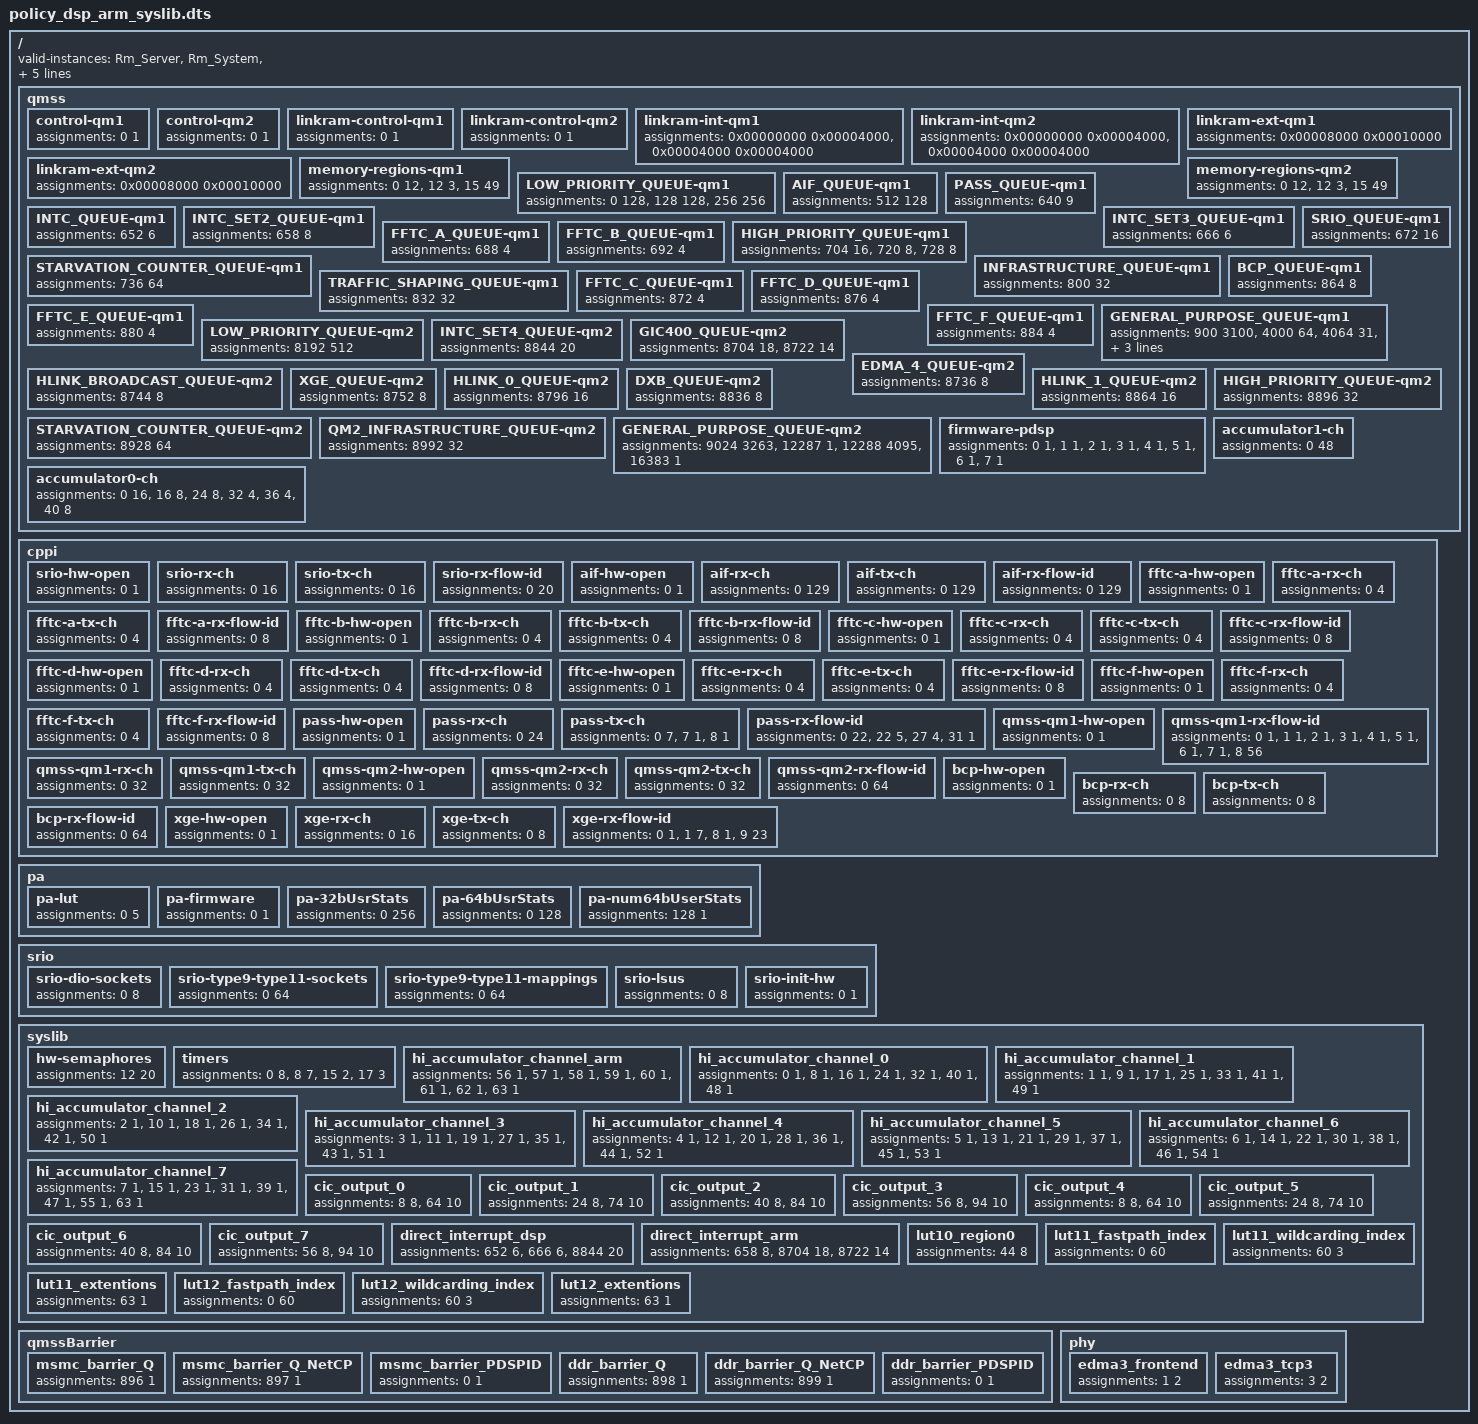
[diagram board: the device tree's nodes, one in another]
/dts-v1/;

/* Keystone II policy containing reserving resources used by Linux Kernel */

/ {
    /* List of Instance names: */
    valid-instances = "Rm_Server",
                      "Rm_System",
                      "Rm_LTE10",
                      "Rm_LTE10_L3",
                      "Rm_LTE10_L2",
                      "Rm_LTE10_L2A",
                      "Rm_LTE10_L2B",
                      "Rm_LTE10_L1A",
                      "Rm_LTE10_L1B",
                      "Rm_LTE9A",
                      "Rm_LTE9A_L1",
                      "Rm_LTE9A_L2",
                      "Rm_LTE9B",
                      "Rm_LTE9B_L1",
                      "Rm_LTE9B_L2";
    qmss {
        /* QMSS in joint mode affects only -qm1 resource */
        control-qm1 {
            assignments = <0 1>, "iu = (*)";
        };
        control-qm2 {
            assignments = <0 1>, "iu = (*)";
        };

        linkram-control-qm1 {
            assignments = <0 1>, "(*)";             /* Used by Kernel */
        };
        linkram-control-qm2 {
            assignments = <0 1>, "(*)";             /* Used by Kernel */
        };

        linkram-int-qm1 {
            /* linux provided 0x18000 descriptors of linking RAM but uses 0x4000 to 0x8000 */
            assignments = <0x00000000 0x00004000>, "iu = (*)",
                          <0x00004000 0x00004000>, "(*)"; /* Used by Kernel */
        };
        linkram-int-qm2 {
            /* linux provided 0x18000 descriptors of linking RAM but uses 0x4000 to 0x8000 */
            assignments = <0x00000000 0x00004000>, "iu = (*)",
                          <0x00004000 0x00004000>, "(*)"; /* Used by Kernel */
        };
        linkram-ext-qm1 {
            assignments = <0x00008000 0x00010000>, "iu = (*)";
        };
        linkram-ext-qm2 {
            assignments = <0x00008000 0x00010000>, "iu = (*)";
        };

        memory-regions-qm1 {
            assignments = <0  12>, "iu = (*)",
                          <12 3>,  "(*)",             /* Used by Kernel */
                          <15 49>, "iu = (*)";
        };
        memory-regions-qm2 {
            assignments = <0  12>, "iu = (*)",
                          <12 3>,  "(*)",             /* Used by Kernel */
                          <15 49>, "iu = (*)";
        };

        LOW_PRIORITY_QUEUE-qm1 {
            /* this is loosely coupled with accumulator-ch channels 32-47.  These queues are
             * just suggested to be paired with these channels, the accumulator can be sw
             * configured to use any queue */
            assignments = <0 128>,   "iu = (*)", /* suggested for channels 32-35 */
                          <128 128>, "     (*)", /* used by linux (accumulator-low-#); linux pairs these to channels 36-39 */
                          <256 256>, "iu = (*)"; /* suggested for channels 40-47 */
        };
        AIF_QUEUE-qm1 {
            assignments = <512 128>, "iu = (*)";
        };
        PASS_QUEUE-qm1 {
            assignments = <640  9>,  "iu = (*)";     /* used by both kernel and DSP */
        };
        INTC_QUEUE-qm1 {
            assignments = <652 6>, "iu = (*)";
        };
        INTC_SET2_QUEUE-qm1 {
            assignments = <658 8>, "iu = (*)";
        };
        INTC_SET3_QUEUE-qm1 {
            assignments = <666 6>, "iu = (*)";
        };
        SRIO_QUEUE-qm1 {
            assignments = <672 16>, "iu = (*)";
        };
        FFTC_A_QUEUE-qm1 {
            assignments = <688 4>, "iu = (*)";
        };
        FFTC_B_QUEUE-qm1 {
            assignments = <692 4>, "iu = (*)";
        };
        HIGH_PRIORITY_QUEUE-qm1 {
            /* this is loosely coupled with accumulator-ch channels 0-15.  These queues are
             * just suggested to be paired with these channels, the accumulator can be sw
             * configured to use any queue */
            assignments = <704 16>, "iu = (*)", /* suggested for channels 0-15 */
                          <720 8>,  "iu = (*)", /* Declared, but not used, by linux (accumulator-high.values). */
                          <728 8>,  "iu = (*)"; /* suggested for channels 24-31 */
        };
        STARVATION_COUNTER_QUEUE-qm1 {
            assignments = <736 64>, "iu = (*)";
        };
        INFRASTRUCTURE_QUEUE-qm1 {
            assignments = <800  32>,   "iu = (*)";
        };
        TRAFFIC_SHAPING_QUEUE-qm1 {
            assignments = <832 32>, "iu = (*)";
        };
        BCP_QUEUE-qm1 {
            assignments = <864 8>, "iu = (*)";
        };
        FFTC_C_QUEUE-qm1 {
            assignments = <872 4>, "iu = (*)";
        };
        FFTC_D_QUEUE-qm1 {
            assignments = <876 4>, "iu = (*)";
        };
        FFTC_E_QUEUE-qm1 {
            assignments = <880 4>, "iu = (*)";
        };
        FFTC_F_QUEUE-qm1 {
            assignments = <884 4>, "iu = (*)";
        };
        GENERAL_PURPOSE_QUEUE-qm1 {
            assignments = /* First 4 queues are reserved for QMSS barrier */
                          /*<896  4>,     "iu = (Rm_System)",*/
                          <900  3100>,  "iu = (*)",
                          <4000 64>,    "(*)",       /* Used by Kernel */
                          <4064 31>,    "iu = (*)",
                          <4095 1>,     "iue = (*)",   /* Queues ending in 0xfff can't be used as return queue (hw reserved) */
                          <4096 2304>,  "iu = (*)",

                          /* 6400-6477 is taken by linux for qostree2, but DSP can transmit via "fastpath" queues */
                          <6400 72>,    "u = (*)",   /* qos queues for DSP (fastpath-best-effort, fastpath-hp, 4g-cos#, 3g-cos#, wifi-cos#) use (open by number) not init */
                          <6472 6>,     "(*)",       /* qos queues for linux (linux-best-effort, linux-cos#, linux-hp) - DSP can't use */
                          <6478 114>,   "(*)",       /* unconfigured QoS/Linux queues (qos-inputs-2) */

                          <6592 1408>,  "iu = (*)",

                          /* 8000-8191 is taken by linux for qostree but DSP can transmit via "fastpath" queues */
                          <8000 72>,    "u = (*)",   /* qos queues for DSP (fastpath-best-effort, fastpath-hp, 4g-cos#, 3g-cos#, wifi-cos#) use (open by number) not init */
                          <8072 6>,     "(*)",       /* qos queues for linux (linux-best-effort, linux-cos#, linux-hp) - DSP can't use */
                          <8078 114>,   "(*)";       /* unconfigured QoS/Linux queues (qos-inputs-1) */
                                                     /* note for q 8191: Queues ending in 0xfff can't be used as return queue (hw reserved) */
        };
        LOW_PRIORITY_QUEUE-qm2 {
            assignments = <8192 512>, "iu = (*)";
        };
        INTC_SET4_QUEUE-qm2 {
            assignments = <8844 20>, "iu = (*)";
        };
        GIC400_QUEUE-qm2 {
            assignments = <8704 18>,    "(*)",             /* Used by Kernel */
                          <8722 14>,   "iu = (*)";
        };
        EDMA_4_QUEUE-qm2 {
            assignments = <8736 8>, "iu = (*)";
        };
        HLINK_BROADCAST_QUEUE-qm2 {
            assignments = <8744 8>, "iu = (*)";
        };
        XGE_QUEUE-qm2 {
            assignments = <8752 8>, "iu = (*)";   /* can be used by both dsp and kernel */
        };
        HLINK_0_QUEUE-qm2 {
            assignments = <8796 16>, "iu = (*)";
        };
        DXB_QUEUE-qm2 {
            assignments = <8836 8>, "iu = (*)";
        };
        HLINK_1_QUEUE-qm2 {
            assignments = <8864 16>, "iu = (*)";
        };
        HIGH_PRIORITY_QUEUE-qm2 {
            assignments = <8896 32>, "iu = (*)";
        };
        STARVATION_COUNTER_QUEUE-qm2 {
            assignments = <8928 64>, "iu = (*)";
        };
        QM2_INFRASTRUCTURE_QUEUE-qm2 {
            assignments = <8992 32>, "iu = (*)";
        };
        GENERAL_PURPOSE_QUEUE-qm2 {
            assignments = <9024 3263>, "iu = (*)",
                          <12287 1>, "iue = (*)", /* Queues ending in 0xfff can't be used as return queue (hw reserved) */
                          <12288 4095>, "iu = (*)",
                          <16383 1>, "iue = (*)"; /* Queues ending in 0xfff can't be used as return queue (hw reserved) */
        }; 
        
        firmware-pdsp {
            assignments = <0 1>, "     (*)", /* pdsp0: accumulator 0 downloaded by linux */
                          <1 1>, "iu = (*)", /* pdsp1: for em scheduler if event machine is used (not downloaded by linux) */
                          <2 1>, "iu = (Rm_System)", /* pdsp2: for accumulator 1 on second intd (not downloaded by linux) */
                          <3 1>, "     (*)", /* pdsp3: qostree downloaded by linux */
                          <4 1>, "iu = (*)", /* pdsp4: for em scheduler if event machine is used (not downloaded by linux) */
                          <5 1>, "iu = (*)", /* pdsp5: for em scheduler if event machine is used (not downloaded by linux) */
                          <6 1>, "iu = (*)", /* pdsp6: for em router if event machine is used (not downloaded by linux) */
                          <7 1>, "     (*)"; /* pdsp7: qostree2 downloaded by linux */
        };
        accumulator0-ch { /* accumulator using first INTD */
            assignments = <0 16>, "iu = (*)",    /* high priority 0-15 available for everyone */
                          <16 8>, "iu = (*)",    /* declared but not used by linux, subject to change */
                          <24 8>, "iu = (*)",    /* last 8 high priority are used by event machine, available in non EM use case */
                          <32 4>, "iu = (*)",    /* first 4 low priority are used by event machine, available in non EM use case */
                          <36 4>, "     (*)",    /* next 4 low priority are used by linux (accumulator-low-#) */
                          <40 8>, "iu = (*)";    /* available for all */
        };
        accumulator1-ch { /* accumulator using second INTD */
            assignments = <0 48>, "iu = (*)";    /* linux doesn't use it */
        };
    }; /* qmss */

    cppi {
        srio-hw-open {
            assignments = <0 1>, "iu = (*)";
        };
        srio-rx-ch {
            assignments = <0 16>, "iu = (*)";
        };
        srio-tx-ch {
            assignments = <0 16>, "iu = (*)";
        };
        srio-rx-flow-id {
            assignments = <0 20>, "iu = (*)";
        };   

        aif-hw-open {
            assignments = <0 1>, "iu = (*)";
        };
        aif-rx-ch {
            assignments = <0 129>, "iu = (*)";
        };
        aif-tx-ch {
            assignments = <0 129>, "iu = (*)";
        };
        aif-rx-flow-id {
            assignments = <0 129>, "iu = (*)";
        };      

        fftc-a-hw-open {
            assignments = <0 1>, "iu = (*)";
        };
        fftc-a-rx-ch {
            assignments = <0 4>, "iu = (*)";
        };
        fftc-a-tx-ch {
            assignments = <0 4>, "iu = (*)";
        };
        fftc-a-rx-flow-id {
            assignments = <0 8>, "iu = (*)";
        };   

        fftc-b-hw-open {
            assignments = <0 1>, "iu = (*)";
        };
        fftc-b-rx-ch {
            assignments = <0 4>, "iu = (*)";
        };
        fftc-b-tx-ch {
            assignments = <0 4>, "iu = (*)";
        };
        fftc-b-rx-flow-id {
            assignments = <0 8>, "iu = (*)";
        };   

        fftc-c-hw-open {
            assignments = <0 1>, "iu = (*)";
        };
        fftc-c-rx-ch {
            assignments = <0 4>, "iu = (*)";
        };
        fftc-c-tx-ch {
            assignments = <0 4>, "iu = (*)";
        };
        fftc-c-rx-flow-id {
            assignments = <0 8>, "iu = (*)";
        };

        fftc-d-hw-open {
            assignments = <0 1>, "iu = (*)";
        };
        fftc-d-rx-ch {
            assignments = <0 4>, "iu = (*)";
        };
        fftc-d-tx-ch {
            assignments = <0 4>, "iu = (*)";
        };
        fftc-d-rx-flow-id {
            assignments = <0 8>, "iu = (*)";
        };   

        fftc-e-hw-open {
            assignments = <0 1>, "iu = (*)";
        };
        fftc-e-rx-ch {
            assignments = <0 4>, "iu = (*)";
        };
        fftc-e-tx-ch {
            assignments = <0 4>, "iu = (*)";
        };
        fftc-e-rx-flow-id {
            assignments = <0 8>, "iu = (*)";
        };

        fftc-f-hw-open {
            assignments = <0 1>, "iu = (*)";
        };
        fftc-f-rx-ch {
            assignments = <0 4>, "iu = (*)";
        };
        fftc-f-tx-ch {
            assignments = <0 4>, "iu = (*)";
        };
        fftc-f-rx-flow-id {
            assignments = <0 8>, "iu = (*)";
        };         
        
        pass-hw-open {
            assignments = <0 1>, "iu = (*)";
        };
        pass-rx-ch {
            assignments = <0 24>, "     (*)"; /* initialized by kernel */
        };
        pass-tx-ch {
            assignments = <0 7>, "     (*)", /* initialized by kernel, can directly open queuse */
                          <7 1>, "iu = (*)", /* SA channel.  Linux initializes, but some applications need to enable/disable on fly */
                          <8 1>, "     (*)"; /* initialized by kernel, can directly open queuse */
        };
        pass-rx-flow-id {
            assignments = <0 22>, "iu = (*)", /* available */
                          <22 5>, "     (*)", /* used by kernel (netrx0, netrx1, netrx2, netrx3, crypto-rx0) */
                          <27 4>, "iu = (*)", /* available */
                          <31 1>, "     (*)"; /* used by kernel (parx) */
        };

        qmss-qm1-hw-open {
            assignments = <0 1>, "iu = (*)";
        };
/*
        qmss-qm1-rx-ch {
            assignments = <0 32>, "iu = (*)";
        };
        qmss-qm1-tx-ch {
            assignments = <0 32>, "iu = (*)";
        };
        qmss-qm1-rx-flow-id {
            assignments = <0 64>, "iu = (*)";
        };
*/
        /*****************************************************************************************
         * NOTE: The name proxy(s) for DSP-ARM communication reserves 2 sets of infrastructure
         * resources which are required used by the agent server in each realm.
         *
         * LTE9A RAT ARM Agent Server resource usage
         *    Local Flow Id  0 :
         *    Rx Channel     0 :
         *    Tx Channel     1 :
         *
         * LTE9A RAT DSP Agent Server resource usage
         *    Local Flow Id  1 :
         *    Rx Channel     1 :
         *    Tx Channel     0 :
         *
         * LTE9A RAT ARM Agent Server resource usage
         *    Local Flow Id  2 :
         *    Rx Channel     2 :
         *    Tx Channel     3 :
         *
         * LTE9A RAT DSP Agent Server resource usage
         *    Local Flow Id  3 :
         *    Rx Channel     3 :
         *    Tx Channel     2 :
         *
         * It is assumed that the name proxy in the DSP is executing in the L2 domain. If this is
         * not the case please change the RM client name accordingly.
         *
         * For the Release 10; the name proxy will execute on the DSP in the L1 domain. The L2 domain
         * whether it executes on DSP/ARM will also execute the name proxy. There could be 2 L2
         * domains L2A handling L1A and L2B handling L2B.
         *
         * The convention is that Flow Id 0, 2, 4, 6 are always used by the SYSLIB servers.
         * Flow Id 1, 3, 5, 7 are available to the applications.
         ********************************************************************************************/
        qmss-qm1-rx-flow-id {
            assignments = <0 1>,  "iu = (Rm_LTE9A Rm_LTE10)",
                          <1 1>,  "iu = (Rm_LTE9A_L2 Rm_LTE10_L1A)",
                          <2 1>,  "iu = (Rm_LTE9B Rm_LTE10)",
                          <3 1>,  "iu = (Rm_LTE9B_L2 Rm_LTE10_L1B)",
                          <4 1>,  "iu = (Rm_LTE10)",
                          <5 1>,  "iu = (Rm_LTE10_L2A)",
                          <6 1>,  "iu = (Rm_LTE10)",
                          <7 1>,  "iu = (Rm_LTE10_L2B)",
                          <8 56>, "iu = (*)";
        };
        qmss-qm1-rx-ch {
            assignments = <0 32>, "iu = (*)";
        };
        qmss-qm1-tx-ch {
            assignments = <0 32>, "iu = (*)";
        };

        qmss-qm2-hw-open {
            assignments = <0 1>, "iu = (*)";
        };
        qmss-qm2-rx-ch {
            assignments = <0 32>, "iu = (*)";
        };
        qmss-qm2-tx-ch {
            assignments = <0 32>, "iu = (*)";
        };
        qmss-qm2-rx-flow-id {
            assignments = <0 64>, "iu = (*)";
        };

        bcp-hw-open {
            assignments = <0 1>, "iu = (*)";
        };
        bcp-rx-ch {
            assignments = <0 8>, "iu = (*)";
        };
        bcp-tx-ch {
            assignments = <0 8>, "iu = (*)";
        };
        bcp-rx-flow-id {
            assignments = <0 64>, "iu = (*)";
        };

        xge-hw-open {
            assignments = <0 1>, "iu = (*)";
        };
        xge-rx-ch {
            assignments = <0 16>, "    (*)"; /* initialized by kernel */
        };
        xge-tx-ch {
            assignments = <0 8>, "     (*)"; /* initialized by kernel, directly open the queues */
        };
        xge-rx-flow-id {
            assignments = <0 1>,  "     (*)", /* used by kernel (xgerx0) */
                          <1 7>,  "iu = (*)", /* available */
                          <8 1>,  "     (*)", /* used by kernel (xgerx1) */
                          <9 23>, "iu = (*)"; /* available */
        };
    }; /* cppi */

    pa {
        pa-lut {
            assignments = <0 5>, "iu = (*)";
        };
        pa-firmware {
            assignments = <0 1>, "(*)"; /* linux downloads PA firmware */
        };
        pa-32bUsrStats {
            assignments = <0 256>, "iu = (*)";
        };
        pa-64bUsrStats {
            assignments = <0 128>, "iu = (*)";
        };
        pa-num64bUserStats {
            assignments = <128 1>, "iu = (*)";
        };
    }; /* pa */

    srio {
        srio-dio-sockets {
            assignments = <0 8>, "iu = (*)";
        };
        srio-type9-type11-sockets {
            assignments = <0 64>, "iu = (*)";
        };
        srio-type9-type11-mappings {
            assignments = <0 64>, "iu = (*)";
        };
        srio-lsus {
            assignments = <0 8>, "iu = (*)";
        };
        srio-init-hw {
            assignments = <0 1>, "iu = (*)";
        };
    };

    syslib {
        /*****************************************************************************
         * Hardware semaphores:
         *  - All hardware semaphores are assigned to all the RM instances
         *****************************************************************************/
        hw-semaphores {
            assignments = <12 20>, "iu = (*)";
        };

        /*****************************************************************************
         * Hardware timers:
         *  - Assign the hardware timers to the all RM instances.
         *  - Each DSP core executing BIOS will take 1 timer.
         *  - Timer 15 is taken up by the Linux kernel.
         *****************************************************************************/
        timers {
            assignments = <0  8>,  "     (*)", /* used by BIOS kernel on DSP cores */
                          <8  7>,  "iu = (*)", /* available */
                          <15 2>,  "     (*)", /* used by kernel */
                          <17 3>,  "iu = (*)"; /* available */
        };

        /*****************************************************************************
         * High Priority accumulated channels:
         *  - Each core has 7 assigned channels each of which is available to all the
         *    RM instances.
         *  - ARM has 8 accumulated channels allocated for its use
         *****************************************************************************/
        hi_accumulator_channel_arm {
            assignments =   <56 1>, "iu = (*)",
                            <57 1>, "iu = (*)",
                            <58 1>, "iu = (*)",
                            <59 1>, "iu = (*)",
                            <60 1>, "iu = (*)",
                            <61 1>, "iu = (*)",
                            <62 1>, "iu = (*)",
                            <63 1>, "iu = (*)";
        };
        hi_accumulator_channel_0 {
            assignments =   <0  1>, "iu = (*)",
                            <8  1>, "iu = (*)",
                            <16 1>, "iu = (*)",
                            <24 1>, "iu = (*)",
                            <32 1>, "iu = (*)",
                            <40 1>, "iu = (*)",
                            <48 1>, "iu = (*)";
        };
        hi_accumulator_channel_1 {
            assignments =   <1  1>, "iu = (*)",
                            <9  1>, "iu = (*)",
                            <17 1>, "iu = (*)",
                            <25 1>, "iu = (*)",
                            <33 1>, "iu = (*)",
                            <41 1>, "iu = (*)",
                            <49 1>, "iu = (*)";
        };
        hi_accumulator_channel_2 {
            assignments =   <2  1>, "iu = (*)",
                            <10 1>, "iu = (*)",
                            <18 1>, "iu = (*)",
                            <26 1>, "iu = (*)",
                            <34 1>, "iu = (*)",
                            <42 1>, "iu = (*)",
                            <50 1>, "iu = (*)";
        };
        hi_accumulator_channel_3 {
            assignments =   <3  1>, "iu = (*)",
                            <11 1>, "iu = (*)",
                            <19 1>, "iu = (*)",
                            <27 1>, "iu = (*)",
                            <35 1>, "iu = (*)",
                            <43 1>, "iu = (*)",
                            <51 1>, "iu = (*)";
        };
        hi_accumulator_channel_4 {
            assignments =   <4  1>, "iu = (*)",
                            <12 1>, "iu = (*)",
                            <20 1>, "iu = (*)",
                            <28 1>, "iu = (*)",
                            <36 1>, "iu = (*)",
                            <44 1>, "iu = (*)",
                            <52 1>, "iu = (*)";
        };
        hi_accumulator_channel_5 {
            assignments =   <5  1>, "iu = (*)",
                            <13 1>, "iu = (*)",
                            <21 1>, "iu = (*)",
                            <29 1>, "iu = (*)",
                            <37 1>, "iu = (*)",
                            <45 1>, "iu = (*)",
                            <53 1>, "iu = (*)";
        };
        hi_accumulator_channel_6 {
            assignments =   <6  1>, "iu = (*)",
                            <14 1>, "iu = (*)",
                            <22 1>, "iu = (*)",
                            <30 1>, "iu = (*)",
                            <38 1>, "iu = (*)",
                            <46 1>, "iu = (*)",
                            <54 1>, "iu = (*)";
        };
        hi_accumulator_channel_7 {
            assignments =   <7  1>, "iu = (*)",
                            <15 1>, "iu = (*)",
                            <23 1>, "iu = (*)",
                            <31 1>, "iu = (*)",
                            <39 1>, "iu = (*)",
                            <47 1>, "iu = (*)",
                            <55 1>, "iu = (*)",
                            <63 1>, "iu = (*)";
        };

        /*****************************************************************************
         * System Interrupt Mappings:
         *  - Each system interrupt on each is available to all RM instances.
         *****************************************************************************/
        cic_output_0 {
            assignments = <8  8>  , "iu = (*)",
                          <64 10> , "iu = (*)";
        };
        cic_output_1 {
            assignments = <24 8>  , "iu = (*)",
                          <74 10> , "iu = (*)";
        };
        cic_output_2 {
            assignments = <40 8>  , "iu = (*)",
                          <84 10> , "iu = (*)";
        };
        cic_output_3 {
            assignments = <56 8>  , "iu = (*)",
                          <94 10> , "iu = (*)";
        };
        cic_output_4 {
            assignments = <8  8>  , "iu = (*)",
                          <64 10> , "iu = (*)";
        };
        cic_output_5 {
            assignments = <24 8>  , "iu = (*)",
                          <74 10> , "iu = (*)";
        };
        cic_output_6 {
            assignments = <40 8>  , "iu = (*)",
                          <84 10> , "iu = (*)";
        };
        cic_output_7 {
            assignments = <56 8>  , "iu = (*)",
                          <94 10> , "iu = (*)";
        };

        /*****************************************************************************
         * Direct Interrupt Mappings:
         *  - On the DSP all the direct interrupt queues are available to all RM
         *    instances
         *  - On ARM however we need to be careful since the GIC queues are also used
         *    by the Linux kernel; so any changes in the GIC queue assignments would
         *    need to be aligned with the kernel DTB file also.
         *  - INTC-SET2 is shared but currently has been allocated to ARM
         *****************************************************************************/
        direct_interrupt_dsp {
            assignments = <652  6>   , "iu = (*)",
                          <666  6>   , "iu = (*)",
                          <8844 20>  , "iu = (*)";
        };
        direct_interrupt_arm {
            assignments = <658  8>  , "iu = (*)",
                          <8704 18> , "     (*)",    /* Used by the Linux kernel. */
                          <8722 14> , "iu = (*)";
        };

        /*****************************************************************************
         * LUT1-0 entries for Ethernet Rules
         ****************************************************************************/
        lut10_region0 {
            assignments = <44 8>, "iu = (*)";
        };

        /*****************************************************************************
         * LUT1 entries
         * - The following section defines how LUT1 entries will be used in fast path
         *   creation
         * - There are 3 groups for both LUT1-1 and LUT1-2
         *   1. Normal Fast Path
         *   2. Wild Carding Fast Path
         *   3. LUT Extension
         *****************************************************************************/
        /* LUT1-1 */
        lut11_fastpath_index {
            assignments = <0 60>, "iu = (*)";
        };
        lut11_wildcarding_index {
            assignments = <60 3>, "iu = (*)";
        };
        lut11_extentions {
            assignments = <63 1>, "     (*)";    /* Reserved */
        };

        /* LUT1-2 */
        lut12_fastpath_index {
            assignments = <0 60>, "iu = (*)";
        };
        lut12_wildcarding_index {
            assignments = <60 3>, "iu = (*)";
        };
        lut12_extentions {
            assignments = <63 1>, "     (*)";    /* Reserved */
        };
    }; /* syslib */

    qmssBarrier {
        msmc_barrier_Q {
            assignments = <896 1>, "iu = (Rm_System)";  /* QMSS MSMC Barrier Queues */
        };
        msmc_barrier_Q_NetCP {
            assignments = <897 1>, "iu = (Rm_System)";  /* QMSS MSMC Barrier Queues */
        };
        msmc_barrier_PDSPID {
            assignments = <0 1>, "iu = (Rm_System)";    /* QMSS MSMC Barrier PDSP ID */
        };
        ddr_barrier_Q {
            assignments = <898 1>, "iu = (Rm_System)";  /* QMSS DDR Barrier Queues */
        };
        ddr_barrier_Q_NetCP {
            assignments = <899 1>, "iu = (Rm_System)";  /* QMSS DDR Barrier Queues */
        };
        ddr_barrier_PDSPID {
            assignments = <0 1>, "iu = (Rm_System)";    /* QMSS DDR Barrier PDSP ID */
        };
    }; /* qmssBarrier */

    phy {
        /*****************************************************************************
         * EDMA3 Instances are used between the PHY front end and TCP3D
         *****************************************************************************/
        edma3_frontend {
            assignments = <1 2>, "iu = (*)";
        };
        edma3_tcp3 {
            assignments = <3 2>, "iu = (*)";
        };
    };  /* phy */
};
